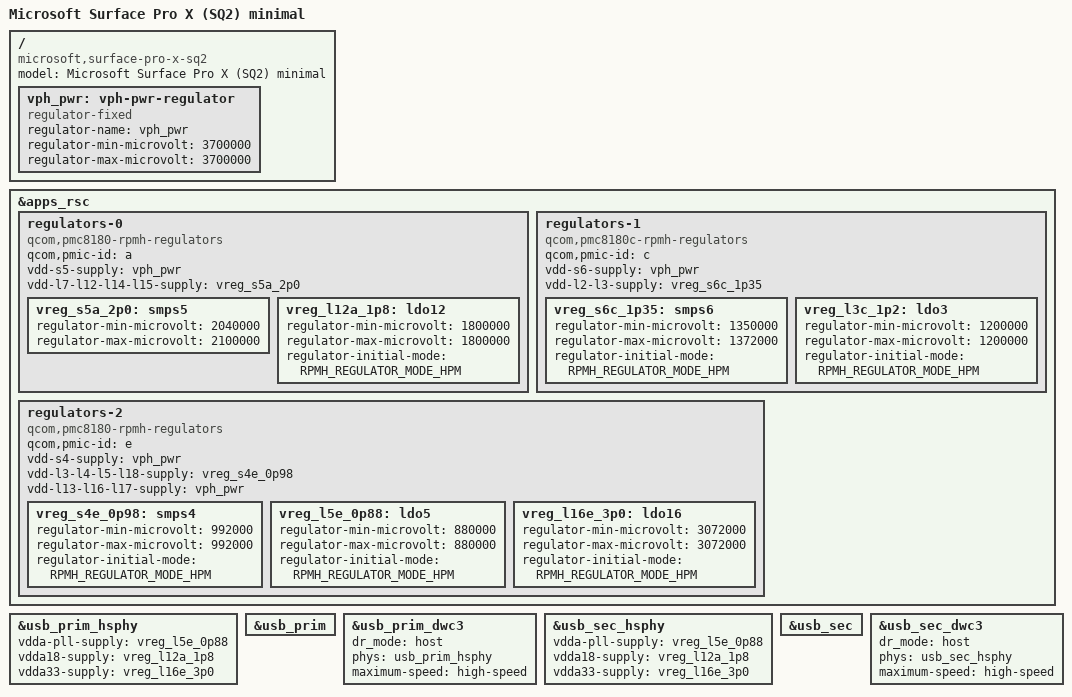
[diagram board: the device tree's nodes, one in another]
// SPDX-License-Identifier: BSD-3-Clause
/*
 * Microsoft Surface Pro X (SQ2) — MINIMAL bring-up DTS.
 *
 * Purpose: USB rootfs boot with the fewest unverified nodes. Everything
 * guessed from Flex 5G (PCIe pins, backlight, lid, display, pmic-glink
 * connector graph) is omitted so it cannot kill the boot or the efifb
 * console. The full board file is sc8180xp-microsoft-surface-pro-x.dts.
 *
 * Enabled: RPMh regulators (USB PHY rails), USB prim/sec controllers and
 * PHYs in host mode. Nothing else.
 */

/dts-v1/;

#include <dt-bindings/regulator/qcom,rpmh-regulator.h>
#include "sc8180xp.dtsi"
#include "sc8180x-pmics.dtsi"

/ {
	model = "Microsoft Surface Pro X (SQ2) minimal";
	compatible = "microsoft,surface-pro-x-sq2", "qcom,sc8180xp",
		     "qcom,sc8180x";

	vph_pwr: vph-pwr-regulator {
		compatible = "regulator-fixed";
		regulator-name = "vph_pwr";
		regulator-min-microvolt = <3700000>;
		regulator-max-microvolt = <3700000>;
	};
};

&apps_rsc {
	regulators-0 {
		compatible = "qcom,pmc8180-rpmh-regulators";
		qcom,pmic-id = "a";

		vdd-s5-supply = <&vph_pwr>;
		vdd-l7-l12-l14-l15-supply = <&vreg_s5a_2p0>;

		vreg_s5a_2p0: smps5 {
			regulator-min-microvolt = <2040000>;
			regulator-max-microvolt = <2100000>;
		};

		vreg_l12a_1p8: ldo12 {
			regulator-min-microvolt = <1800000>;
			regulator-max-microvolt = <1800000>;
			regulator-initial-mode = <RPMH_REGULATOR_MODE_HPM>;
		};
	};

	regulators-1 {
		compatible = "qcom,pmc8180c-rpmh-regulators";
		qcom,pmic-id = "c";

		vdd-s6-supply = <&vph_pwr>;
		vdd-l2-l3-supply = <&vreg_s6c_1p35>;

		vreg_s6c_1p35: smps6 {
			regulator-min-microvolt = <1350000>;
			regulator-max-microvolt = <1372000>;
			regulator-initial-mode = <RPMH_REGULATOR_MODE_HPM>;
		};

		vreg_l3c_1p2: ldo3 {
			regulator-min-microvolt = <1200000>;
			regulator-max-microvolt = <1200000>;
			regulator-initial-mode = <RPMH_REGULATOR_MODE_HPM>;
		};
	};

	regulators-2 {
		compatible = "qcom,pmc8180-rpmh-regulators";
		qcom,pmic-id = "e";

		vdd-s4-supply = <&vph_pwr>;
		vdd-l3-l4-l5-l18-supply = <&vreg_s4e_0p98>;
		vdd-l13-l16-l17-supply = <&vph_pwr>;

		vreg_s4e_0p98: smps4 {
			regulator-min-microvolt = <992000>;
			regulator-max-microvolt = <992000>;
			regulator-initial-mode = <RPMH_REGULATOR_MODE_HPM>;
		};

		vreg_l5e_0p88: ldo5 {
			regulator-min-microvolt = <880000>;
			regulator-max-microvolt = <880000>;
			regulator-initial-mode = <RPMH_REGULATOR_MODE_HPM>;
		};

		vreg_l16e_3p0: ldo16 {
			regulator-min-microvolt = <3072000>;
			regulator-max-microvolt = <3072000>;
			regulator-initial-mode = <RPMH_REGULATOR_MODE_HPM>;
		};
	};
};

/*
 * USB2 (high-speed) only for bring-up: the QMP combo PHY (USB3+DP) is the
 * prime SError suspect — its register region may be unclocked depending on
 * what state the firmware left. The SNPS femto HS PHY is self-contained.
 * 480 Mbps is plenty for a USB rootfs.
 */
&usb_prim_hsphy {
	vdda-pll-supply = <&vreg_l5e_0p88>;
	vdda18-supply = <&vreg_l12a_1p8>;
	vdda33-supply = <&vreg_l16e_3p0>;

	status = "okay";
};

&usb_prim {
	status = "okay";
};

&usb_prim_dwc3 {
	dr_mode = "host";
	phys = <&usb_prim_hsphy>;
	phy-names = "usb2-phy";
	maximum-speed = "high-speed";
};

&usb_sec_hsphy {
	vdda-pll-supply = <&vreg_l5e_0p88>;
	vdda18-supply = <&vreg_l12a_1p8>;
	vdda33-supply = <&vreg_l16e_3p0>;

	status = "okay";
};

&usb_sec {
	status = "okay";
};

&usb_sec_dwc3 {
	dr_mode = "host";
	phys = <&usb_sec_hsphy>;
	phy-names = "usb2-phy";
	maximum-speed = "high-speed";
};
